# STM32H7R register map
File version: 1.3
CPU: CM7 r0p1, little endian, MPU, FPU, 4 interrupt priority bits
Registers are 32-bit, read-write, reset 0x0 unless marked. A register's access mark holds for its fields unless they carry their own. Offsets are from the block's base; [hi:lo] are bit positions; 'fields as' and 'values as' point back to an identical list.

## SAI1 — Serial audio interface
Base 0x42005800
Same registers: SAI2 0x42005C00
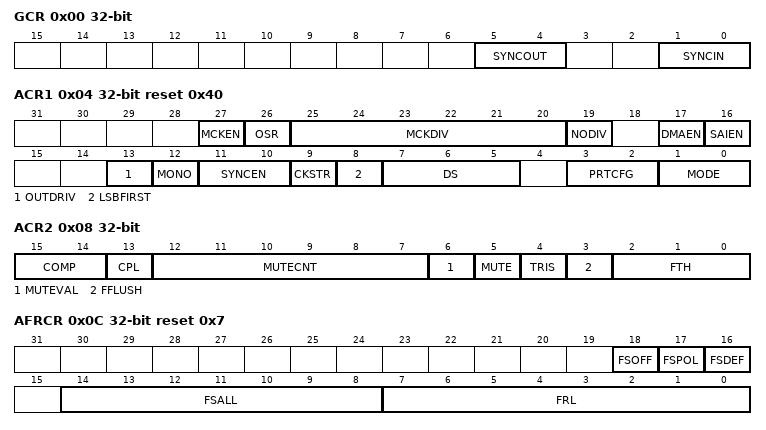
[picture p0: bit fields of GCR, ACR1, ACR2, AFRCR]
0x00 GCR — SAI global configuration register
  [5:4] SYNCOUT — Synchronization outputs These bits are set and cleared by software.
  [1:0] SYNCIN — Synchronization inputs These bits are set and cleared by software. Refer to Table 418: External synchronization selection (TinyShark, Beluga and STM32U5_Cobra2M and 4M, Viper, Mustang, Python) for information on how to program this field. These bits must be set when both audio blocks (A and B) are disabled. They are meaningful if one of the two audio blocks is defined to operate in synchronous mode with an external SAI (SYNCEN[1:0] = 10 in SAI_ACR1 or in SAI_BCR1 registers).
0x04 ACR1 reset 0x40 — SAI configuration register 1
  [27] MCKEN — Master clock generation enable
  [26] OSR — Oversampling ratio for master clock This bit is meaningful only when NODIV bit is set to 0.
  [25:20] MCKDIV — Master clock divider These bits are set and cleared by software. Otherwise, The master clock frequency is calculated according to the formula given in Section 55.4.8: SAI clock generator. These bits have no meaning when the audio block is slave. They have to be configured when the audio block is disabled.
  [19] NODIV — No divider This bit is set and cleared by software.
  [17] DMAEN — DMA enable This bit is set and cleared by software. Note: Since the audio block defaults to operate as a transmitter after reset, the MODE[1:0] bits must be configured before setting DMAEN to avoid a DMA request in receiver mode.
  [16] SAIEN — Audio block enable This bit is set by software. To switch off the audio block, the application software must program this bit to 0 and poll the bit till it reads back 0, meaning that the block is completely disabled. Before setting this bit to 1, check that it is set to 0, otherwise the enable command is not taken into account. This bit enables to control the state of the SAI audio block. If it is disabled when an audio frame transfer is ongoing, the ongoing transfer completes and the cell is fully disabled at the end of this audio frame transfer. Note: When the SAI block (A or B) is configured in master mode, the clock must be present on the SAI block input before setting SAIEN bit.
  [13] OUTDRIV — Output drive This bit is set and cleared by software. Note: This bit has to be set before enabling the audio block and after the audio block configuration.
  [12] MONO — Mono mode This bit is set and cleared by software. It is meaningful only when the number of slots is equal to 2. When the mono mode is selected, slot 0 data are duplicated on slot 1 when the audio block operates as a transmitter. In reception mode, the slot1 is discarded and only the data received from slot 0 are stored. Refer to Section : Mono/stereo mode for more details.
  [11:10] SYNCEN — Synchronization enable These bits are set and cleared by software. They must be configured when the audio subblock is disabled. Note: The audio subblock should be configured as asynchronous when SPDIF mode is enabled.
  [9] CKSTR — Clock strobing edge This bit is set and cleared by software. It must be configured when the audio block is disabled. This bit has no meaning in SPDIF audio protocol.
  [8] LSBFIRST — Least significant bit first This bit is set and cleared by software. It must be configured when the audio block is disabled. This bit has no meaning in AC97 audio protocol since AC97 data are always transferred with the MSB first. This bit has no meaning in SPDIF audio protocol since in SPDIF data are always transferred with LSB first.
  [7:5] DS — Data size These bits are set and cleared by software. These bits are ignored when the SPDIF protocols are selected (bit PRTCFG[1:0]), because the frame and the data size are fixed in such case. When the companding mode is selected through COMP[1:0] bits, DS[1:0] are ignored since the data size is fixed to 8 bits by the algorithm. These bits must be configured when the audio block is disabled.
  [3:2] PRTCFG — Protocol configuration These bits are set and cleared by software. These bits have to be configured when the audio block is disabled.
  [1:0] MODE — SAIx audio block mode These bits are set and cleared by software. They must be configured when SAIx audio block is disabled. Note: When the audio block is configured in SPDIF mode, the master transmitter mode is forced (MODE[1:0] = 00).
0x08 ACR2 access per field — SAI configuration register 2
  [15:14] COMP rw — Companding mode. These bits are set and cleared by software. The -Law and the A-Law log are a part of the CCITT G.711 recommendation, the type of complement that is used depends on CPL bit. The data expansion or data compression are determined by the state of bit MODE[0]. The data compression is applied if the audio block is configured as a transmitter. The data expansion is automatically applied when the audio block is configured as a receiver. Refer to Section : Companding mode for more details. Note: Companding mode is applicable only when Free protocol mode is selected.
  [13] CPL rw — Complement bit. This bit is set and cleared by software. It defines the type of complement to be used for companding mode Note: This bit has effect only when the companding mode is -Law algorithm or A-Law algorithm.
  [12:7] MUTECNT rw — Mute counter. These bits are set and cleared by software. They are used only in reception mode. The value set in these bits is compared to the number of consecutive mute frames detected in reception. When the number of mute frames is equal to this value, the flag MUTEDET is set and an interrupt is generated if bit MUTEDETIE is set. Refer to Section : Mute mode for more details.
  [6] MUTEVAL rw — Mute value. This bit is set and cleared by software.It must be written before enabling the audio block: SAIEN. This bit is meaningful only when the audio block operates as a transmitter, the number of slots is lower or equal to 2 and the MUTE bit is set. If more slots are declared, the bit value sent during the transmission in mute mode is equal to 0, whatever the value of MUTEVAL. if the number of slot is lower or equal to 2 and MUTEVAL = 1, the MUTE value transmitted for each slot is the one sent during the previous frame. Refer to Section : Mute mode for more details. Note: This bit is meaningless and should not be used for SPDIF audio blocks.
  [5] MUTE rw — Mute. This bit is set and cleared by software. It is meaningful only when the audio block operates as a transmitter. The MUTE value is linked to value of MUTEVAL if the number of slots is lower or equal to 2, or equal to 0 if it is greater than 2. Refer to Section : Mute mode for more details. Note: This bit is meaningless and should not be used for SPDIF audio blocks.
  [4] TRIS rw — Tristate management on data line. This bit is set and cleared by software. It is meaningful only if the audio block is configured as a transmitter. This bit is not used when the audio block is configured in SPDIF mode. It should be configured when SAI is disabled. Refer to Section : Output data line management on an inactive slot for more details.
  [3] FFLUSH wo — FIFO flush. This bit is set by software. It is always read as 0. This bit should be configured when the SAI is disabled.
  [2:0] FTH rw — FIFO threshold. This bit is set and cleared by software.
0x0C AFRCR reset 0x7 — SAI frame configuration register
  [18] FSOFF — Frame synchronization offset. This bit is set and cleared by software. It is meaningless and is not used in AC97 or SPDIF audio block configuration. This bit must be configured when the audio block is disabled.
  [17] FSPOL — Frame synchronization polarity. This bit is set and cleared by software. It is used to configure the level of the start of frame on the FS signal. It is meaningless and is not used in AC97 or SPDIF audio block configuration. This bit must be configured when the audio block is disabled.
  [16] FSDEF — Frame synchronization definition. This bit is set and cleared by software. When the bit is set, the number of slots defined in the SAI_xSLOTR register has to be even. It means that half of this number of slots are dedicated to the left channel and the other slots for the right channel (e.g: this bit has to be set for I2S or MSB/LSB-justified protocols...). This bit is meaningless and is not used in AC97 or SPDIF audio block configuration. It must be configured when the audio block is disabled.
  [14:8] FSALL — Frame synchronization active level length. These bits are set and cleared by software. They specify the length in number of bit clock (SCK) + 1 (FSALL[6:0] + 1) of the active level of the FS signal in the audio frame These bits are meaningless and are not used in AC97 or SPDIF audio block configuration. They must be configured when the audio block is disabled.
  [7:0] FRL — Frame length. These bits are set and cleared by software. They define the audio frame length expressed in number of SCK clock cycles: the number of bits in the frame is equal to FRL[7:0] + 1. The minimum number of bits to transfer in an audio frame must be equal to 8, otherwise the audio block behaves in an unexpected way. This is the case when the data size is 8 bits and only one slot 0 is defined in NBSLOT[4:0] of SAI_xSLOTR register (NBSLOT[3:0] = 0000). In master mode, if the master clock (available on MCLK_x pin) is used, the frame length should be aligned with a number equal to a power of 2, ranging from 8 to 256. When the master clock is not used (NODIV = 1), it is recommended to program the frame length to an value ranging from 8 to 256. These bits are meaningless and are not used in AC97 or SPDIF audio block configuration. They must be configured when the audio block is disabled.
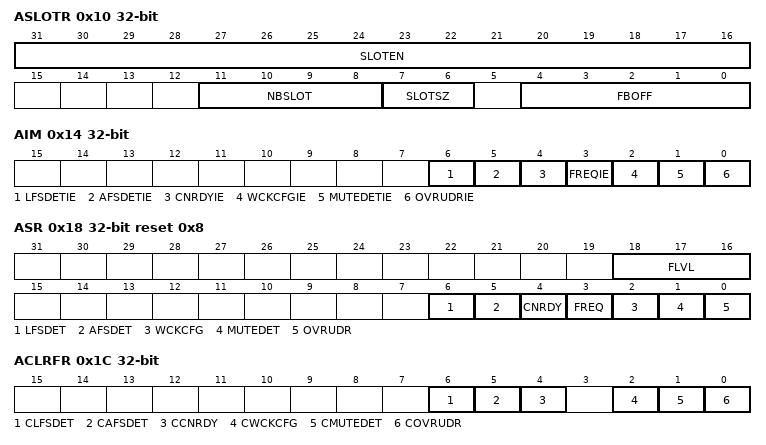
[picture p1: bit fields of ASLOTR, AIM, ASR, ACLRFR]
0x10 ASLOTR — SAI slot register
  [31:16] SLOTEN — Slot enable. These bits are set and cleared by software. Each SLOTEN bit corresponds to a slot position from 0 to 15 (maximum 16 slots). The slot must be enabled when the audio block is disabled. They are ignored in AC97 or SPDIF mode.
  [11:8] NBSLOT — Number of slots in an audio frame. These bits are set and cleared by software. The value set in this bitfield represents the number of slots + 1 in the audio frame (including the number of inactive slots). The maximum number of slots is 16. The number of slots should be even if FSDEF bit in the SAI_xFRCR register is set. The number of slots must be configured when the audio block is disabled. They are ignored in AC97 or SPDIF mode.
  [7:6] SLOTSZ — Slot size This bits is set and cleared by software. The slot size must be higher or equal to the data size. If this condition is not respected, the behavior of the SAI is undetermined. Refer to Output data line management on an inactive slot for information on how to drive SD line. These bits must be set when the audio block is disabled. They are ignored in AC97 or SPDIF mode.
  [4:0] FBOFF — First bit offset These bits are set and cleared by software. The value set in this bitfield defines the position of the first data transfer bit in the slot. It represents an offset value. In transmission mode, the bits outside the data field are forced to 0. In reception mode, the extra received bits are discarded. These bits must be set when the audio block is disabled. They are ignored in AC97 or SPDIF mode.
0x14 AIM — SAI interrupt mask register
  [6] LFSDETIE — Late frame synchronization detection interrupt enable. This bit is set and cleared by software. When this bit is set, an interrupt is generated if the LFSDET bit is set in the SAI_xSR register. This bit is meaningless in AC97, SPDIF mode or when the audio block operates as a master.
  [5] AFSDETIE — Anticipated frame synchronization detection interrupt enable. This bit is set and cleared by software. When this bit is set, an interrupt is generated if the AFSDET bit in the SAI_xSR register is set. This bit is meaningless in AC97, SPDIF mode or when the audio block operates as a master.
  [4] CNRDYIE — Codec not ready interrupt enable (AC97). This bit is set and cleared by software. When the interrupt is enabled, the audio block detects in the slot 0 (tag0) of the AC97 frame if the Codec connected to this line is ready or not. If it is not ready, the CNRDY flag in the SAI_xSR register is set and an interrupt is generated. This bit has a meaning only if the AC97 mode is selected through PRTCFG[1:0] bits and the audio block is operates as a receiver.
  [3] FREQIE — FIFO request interrupt enable. This bit is set and cleared by software. When this bit is set, an interrupt is generated if the FREQ bit in the SAI_xSR register is set. Since the audio block defaults to operate as a transmitter after reset, the MODE bit must be configured before setting FREQIE to avoid a parasitic interrupt in receiver mode,
  [2] WCKCFGIE — Wrong clock configuration interrupt enable. This bit is set and cleared by software. This bit is taken into account only if the audio block is configured as a master (MODE[1] = 0) and NODIV = 0. It generates an interrupt if the WCKCFG flag in the SAI_xSR register is set. Note: This bit is used only in Free protocol mode and is meaningless in other modes.
  [1] MUTEDETIE — Mute detection interrupt enable. This bit is set and cleared by software. When this bit is set, an interrupt is generated if the MUTEDET bit in the SAI_xSR register is set. This bit has a meaning only if the audio block is configured in receiver mode.
  [0] OVRUDRIE — Overrun/underrun interrupt enable. This bit is set and cleared by software. When this bit is set, an interrupt is generated if the OVRUDR bit in the SAI_xSR register is set.
0x18 ASR ro reset 0x8 — SAI status register
  [18:16] FLVL — FIFO level threshold. This bit is read only. The FIFO level threshold flag is managed only by hardware and its setting depends on SAI block configuration (transmitter or receiver mode). Others: Reserved
  [6] LFSDET — Late frame synchronization detection. This bit is read only. This flag can be set only if the audio block is configured in slave mode. It is not used in AC97 or SPDIF mode. It can generate an interrupt if LFSDETIE bit is set in the SAI_xIM register. This flag is cleared when the software sets bit CLFSDET in SAI_xCLRFR register
  [5] AFSDET — Anticipated frame synchronization detection. This bit is read only. This flag can be set only if the audio block is configured in slave mode. It is not used in AC97 or SPDIF mode. It can generate an interrupt if AFSDETIE bit is set in SAI_xIM register. This flag is cleared when the software sets CAFSDET bit in SAI_xCLRFR register.
  [4] CNRDY — Codec not ready. This bit is read only. This bit is used only when the AC97 audio protocol is selected in the SAI_xCR1 register and configured in receiver mode. It can generate an interrupt if CNRDYIE bit is set in SAI_xIM register. This flag is cleared when the software sets CCNRDY bit in SAI_xCLRFR register.
  [3] FREQ — FIFO request. This bit is read only. The request depends on the audio block configuration: If the block is configured in transmission mode, the FIFO request is related to a write request operation in the SAI_xDR. If the block configured in reception, the FIFO request related to a read request operation from the SAI_xDR. This flag can generate an interrupt if FREQIE bit is set in SAI_xIM register.
  [2] WCKCFG — Wrong clock configuration flag. This bit is read only. This bit is used only when the audio block operates in master mode (MODE[1] = 0) and NODIV = 0. It can generate an interrupt if WCKCFGIE bit is set in SAI_xIM register. This flag is cleared when the software sets CWCKCFG bit in SAI_xCLRFR register.
  [1] MUTEDET — Mute detection. This bit is read only. This flag is set if consecutive 0 values are received in each slot of a given audio frame and for a consecutive number of audio frames (set in the MUTECNT bit in the SAI_xCR2 register). It can generate an interrupt if MUTEDETIE bit is set in SAI_xIM register. This flag is cleared when the software sets bit CMUTEDET in the SAI_xCLRFR register.
  [0] OVRUDR — Overrun / underrun. This bit is read only. The overrun and underrun conditions can occur only when the audio block is configured as a receiver and a transmitter, respectively. It can generate an interrupt if OVRUDRIE bit is set in SAI_xIM register. This flag is cleared when the software sets COVRUDR bit in SAI_xCLRFR register.
0x1C ACLRFR wo — SAI clear flag register
  [6] CLFSDET — Clear late frame synchronization detection flag. This bit is write only. Programming this bit to 1 clears the LFSDET flag in the SAI_xSR register. This bit is not used in AC97 or SPDIF mode Reading this bit always returns the value 0.
  [5] CAFSDET — Clear anticipated frame synchronization detection flag. This bit is write only. Programming this bit to 1 clears the AFSDET flag in the SAI_xSR register. It is not used in AC97 or SPDIF mode. Reading this bit always returns the value 0.
  [4] CCNRDY — Clear Codec not ready flag. This bit is write only. Programming this bit to 1 clears the CNRDY flag in the SAI_xSR register. This bit is used only when the AC97 audio protocol is selected in the SAI_xCR1 register. Reading this bit always returns the value 0.
  [2] CWCKCFG — Clear wrong clock configuration flag. This bit is write only. Programming this bit to 1 clears the WCKCFG flag in the SAI_xSR register. This bit is used only when the audio block is set as master (MODE[1] = 0) and NODIV = 0 in the SAI_xCR1 register. Reading this bit always returns the value 0.
  [1] CMUTEDET — Mute detection flag. This bit is write only. Programming this bit to 1 clears the MUTEDET flag in the SAI_xSR register. Reading this bit always returns the value 0.
  [0] COVRUDR — Clear overrun / underrun. This bit is write only. Programming this bit to 1 clears the OVRUDR flag in the SAI_xSR register. Reading this bit always returns the value 0.
0x20 ADR — SAI data register
  [31:0] DATA — Data A write to this register loads the FIFO provided the FIFO is not full. A read from this register empties the FIFO if the FIFO is not empty.
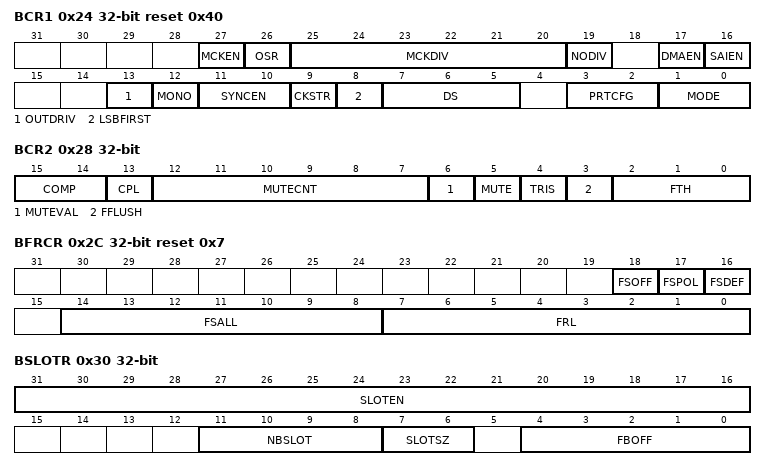
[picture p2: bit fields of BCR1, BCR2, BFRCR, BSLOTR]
0x24 BCR1 reset 0x40 — SAI configuration register 1
  [27] MCKEN — Master clock generation enable
  [26] OSR — Oversampling ratio for master clock This bit is meaningful only when NODIV bit is set to 0.
  [25:20] MCKDIV — Master clock divider These bits are set and cleared by software. Otherwise, The master clock frequency is calculated according to the formula given in Section 55.4.8: SAI clock generator. These bits have no meaning when the audio block is slave. They have to be configured when the audio block is disabled.
  [19] NODIV — No divider This bit is set and cleared by software.
  [17] DMAEN — DMA enable This bit is set and cleared by software. Note: Since the audio block defaults to operate as a transmitter after reset, the MODE[1:0] bits must be configured before setting DMAEN to avoid a DMA request in receiver mode.
  [16] SAIEN — Audio block enable This bit is set by software. To switch off the audio block, the application software must program this bit to 0 and poll the bit till it reads back 0, meaning that the block is completely disabled. Before setting this bit to 1, check that it is set to 0, otherwise the enable command is not taken into account. This bit enables to control the state of the SAI audio block. If it is disabled when an audio frame transfer is ongoing, the ongoing transfer completes and the cell is fully disabled at the end of this audio frame transfer. Note: When the SAI block (A or B) is configured in master mode, the clock must be present on the SAI block input before setting SAIEN bit.
  [13] OUTDRIV — Output drive This bit is set and cleared by software. Note: This bit has to be set before enabling the audio block and after the audio block configuration.
  [12] MONO — Mono mode This bit is set and cleared by software. It is meaningful only when the number of slots is equal to 2. When the mono mode is selected, slot 0 data are duplicated on slot 1 when the audio block operates as a transmitter. In reception mode, the slot1 is discarded and only the data received from slot 0 are stored. Refer to Section : Mono/stereo mode for more details.
  [11:10] SYNCEN — Synchronization enable These bits are set and cleared by software. They must be configured when the audio subblock is disabled. Note: The audio subblock should be configured as asynchronous when SPDIF mode is enabled.
  [9] CKSTR — Clock strobing edge This bit is set and cleared by software. It must be configured when the audio block is disabled. This bit has no meaning in SPDIF audio protocol.
  [8] LSBFIRST — Least significant bit first This bit is set and cleared by software. It must be configured when the audio block is disabled. This bit has no meaning in AC97 audio protocol since AC97 data are always transferred with the MSB first. This bit has no meaning in SPDIF audio protocol since in SPDIF data are always transferred with LSB first.
  [7:5] DS — Data size These bits are set and cleared by software. These bits are ignored when the SPDIF protocols are selected (bit PRTCFG[1:0]), because the frame and the data size are fixed in such case. When the companding mode is selected through COMP[1:0] bits, DS[1:0] are ignored since the data size is fixed to 8 bits by the algorithm. These bits must be configured when the audio block is disabled.
  [3:2] PRTCFG — Protocol configuration These bits are set and cleared by software. These bits have to be configured when the audio block is disabled.
  [1:0] MODE — SAIx audio block mode These bits are set and cleared by software. They must be configured when SAIx audio block is disabled. Note: When the audio block is configured in SPDIF mode, the master transmitter mode is forced (MODE[1:0] = 00). In Master transmitter mode, the audio block starts generating the FS and the clocks immediately.
0x28 BCR2 access per field — SAI configuration register 2
  fields as ACR2
0x2C BFRCR reset 0x7 — SAI frame configuration register
  [18] FSOFF — Frame synchronization offset. This bit is set and cleared by software. It is meaningless and is not used in AC97 or SPDIF audio block configuration. This bit must be configured when the audio block is disabled.
  [17] FSPOL — Frame synchronization polarity. This bit is set and cleared by software. It is used to configure the level of the start of frame on the FS signal. It is meaningless and is not used in AC97 or SPDIF audio block configuration. This bit must be configured when the audio block is disabled.
  [16] FSDEF — Frame synchronization definition. This bit is set and cleared by software. When the bit is set, the number of slots defined in the SAI_xSLOTR register has to be even. It means that half of this number of slots is dedicated to the left channel and the other slots for the right channel (e.g: this bit has to be set for I2S or MSB/LSB-justified protocols...). This bit is meaningless and is not used in AC97 or SPDIF audio block configuration. It must be configured when the audio block is disabled.
  [14:8] FSALL — Frame synchronization active level length. These bits are set and cleared by software. They specify the length in number of bit clock (SCK) + 1 (FSALL[6:0] + 1) of the active level of the FS signal in the audio frame These bits are meaningless and are not used in AC97 or SPDIF audio block configuration. They must be configured when the audio block is disabled.
  [7:0] FRL — Frame length. These bits are set and cleared by software. They define the audio frame length expressed in number of SCK clock cycles: the number of bits in the frame is equal to FRL[7:0] + 1. The minimum number of bits to transfer in an audio frame must be equal to 8, otherwise the audio block behaves in an unexpected way. This is the case when the data size is 8 bits and only one slot 0 is defined in NBSLOT[4:0] of SAI_xSLOTR register (NBSLOT[3:0] = 0000). In master mode, if the master clock (available on MCLK_x pin) is used, the frame length should be aligned with a number equal to a power of 2, ranging from 8 to 256. When the master clock is not used (NODIV = 1), it is recommended to program the frame length to an value ranging from 8 to 256. These bits are meaningless and are not used in AC97 or SPDIF audio block configuration.
0x30 BSLOTR — SAI slot register
  fields as ASLOTR
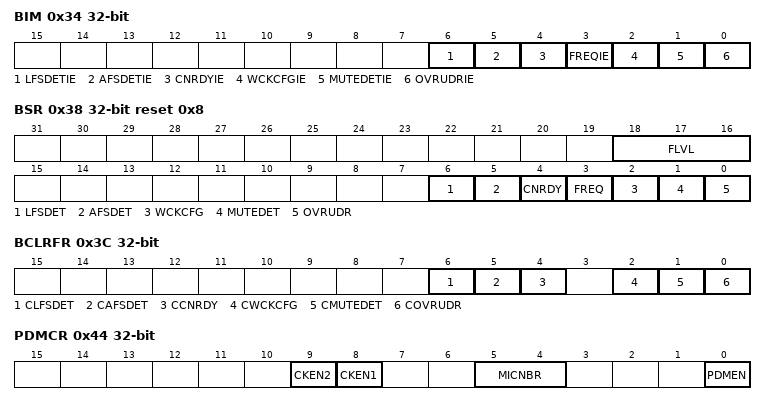
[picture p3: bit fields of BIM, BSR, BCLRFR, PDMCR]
0x34 BIM — SAI interrupt mask register
  fields as AIM
0x38 BSR ro reset 0x8 — SAI status register
  [18:16] FLVL — FIFO level threshold. This bit is read only. The FIFO level threshold flag is managed only by hardware and its setting depends on SAI block configuration (transmitter or receiver mode). Others: Reserved
  [6] LFSDET — Late frame synchronization detection. This bit is read only. This flag can be set only if the audio block is configured in slave mode. It is not used in AC97 or SPDIF mode. It can generate an interrupt if LFSDETIE bit is set in the SAI_xIM register. This flag is cleared when the software sets bit CLFSDET in SAI_xCLRFR register
  [5] AFSDET — Anticipated frame synchronization detection. This bit is read only. This flag can be set only if the audio block is configured in slave mode. It is not used in AC97or SPDIF mode. It can generate an interrupt if AFSDETIE bit is set in SAI_xIM register. This flag is cleared when the software sets CAFSDET bit in SAI_xCLRFR register.
  [4] CNRDY — Codec not ready. This bit is read only. This bit is used only when the AC97 audio protocol is selected in the SAI_xCR1 register and configured in receiver mode. It can generate an interrupt if CNRDYIE bit is set in SAI_xIM register. This flag is cleared when the software sets CCNRDY bit in SAI_xCLRFR register.
  [3] FREQ — FIFO request. This bit is read only. The request depends on the audio block configuration: If the block is configured in transmission mode, the FIFO request is related to a write request operation in the SAI_xDR. If the block configured in reception, the FIFO request related to a read request operation from the SAI_xDR. This flag can generate an interrupt if FREQIE bit is set in SAI_xIM register.
  [2] WCKCFG — Wrong clock configuration flag. This bit is read only. This bit is used only when the audio block operates in master mode (MODE[1] = 0) and NODIV = 0. It can generate an interrupt if WCKCFGIE bit is set in SAI_xIM register. This flag is cleared when the software sets CWCKCFG bit in SAI_xCLRFR register.
  [1] MUTEDET — Mute detection. This bit is read only. This flag is set if consecutive 0 values are received in each slot of a given audio frame and for a consecutive number of audio frames (set in the MUTECNT bit in the SAI_xCR2 register). It can generate an interrupt if MUTEDETIE bit is set in SAI_xIM register. This flag is cleared when the software sets bit CMUTEDET in the SAI_xCLRFR register.
  [0] OVRUDR — Overrun / underrun. This bit is read only. The overrun and underrun conditions can occur only when the audio block is configured as a receiver and a transmitter, respectively. It can generate an interrupt if OVRUDRIE bit is set in SAI_xIM register. This flag is cleared when the software sets COVRUDR bit in SAI_xCLRFR register.
0x3C BCLRFR wo — SAI clear flag register
  [6] CLFSDET — Clear late frame synchronization detection flag. This bit is write only. Programming this bit to 1 clears the LFSDET flag in the SAI_xSR register. This bit is not used in AC97or SPDIF mode Reading this bit always returns the value 0.
  [5] CAFSDET — Clear anticipated frame synchronization detection flag. This bit is write only. Programming this bit to 1 clears the AFSDET flag in the SAI_xSR register. It is not used in AC97or SPDIF mode. Reading this bit always returns the value 0.
  [4] CCNRDY — Clear Codec not ready flag. This bit is write only. Programming this bit to 1 clears the CNRDY flag in the SAI_xSR register. This bit is used only when the AC97 audio protocol is selected in the SAI_xCR1 register. Reading this bit always returns the value 0.
  [2] CWCKCFG — Clear wrong clock configuration flag. This bit is write only. Programming this bit to 1 clears the WCKCFG flag in the SAI_xSR register. This bit is used only when the audio block is set as master (MODE[1] = 0) and NODIV = 0 in the SAI_xCR1 register. Reading this bit always returns the value 0.
  [1] CMUTEDET — Mute detection flag. This bit is write only. Programming this bit to 1 clears the MUTEDET flag in the SAI_xSR register. Reading this bit always returns the value 0.
  [0] COVRUDR — Clear overrun / underrun. This bit is write only. Programming this bit to 1 clears the OVRUDR flag in the SAI_xSR register. Reading this bit always returns the value 0.
0x40 BDR — SAI data register
  fields as ADR
0x44 PDMCR — SAI PDM control register
  [9] CKEN2 — Clock enable of bitstream clock number 2 This bit is set and cleared by software. Note: It is not recommended to configure this bit when PDMEN = 1. Note: SAI_CK2 might not be available for all SAI instances. Refer to Section 55.3: SAI implementation for details.
  [8] CKEN1 — Clock enable of bitstream clock number 1 This bit is set and cleared by software. Note: It is not recommended to configure this bit when PDMEN = 1. Note: SAI_CK1 might not be available for all SAI instances. Refer to Section 55.3: SAI implementation for details.
  [5:4] MICNBR — Number of microphones This bit is set and cleared by software. Note: It is not recommended to configure this field when PDMEN = 1.* Note: The complete set of data lines might not be available for all SAI instances. Refer to Section 55.3: SAI implementation for details.
  [0] PDMEN — PDM enable This bit is set and cleared by software. This bit enables to control the state of the PDM interface block. Make sure that the SAI in already operating in TDM master mode before enabling the PDM interface.
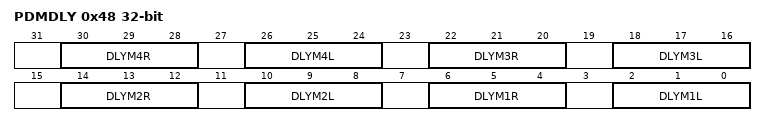
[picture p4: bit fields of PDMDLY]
0x48 PDMDLY — SAI PDM delay register
  [30:28] DLYM4R — Delay line for second microphone of pair 4 This bit is set and cleared by software. ... This field can be changed on-the-fly. Note: This field can be used only if D4 line is available.Refer to Section 55.3: SAI implementation to check if it is available.
  [26:24] DLYM4L — Delay line for first microphone of pair 4 This bit is set and cleared by software. ... This field can be changed on-the-fly. Note: This field can be used only if D4 line is available.Refer to Section 55.3: SAI implementation to check if it is available.
  [22:20] DLYM3R — Delay line for second microphone of pair 3 This bit is set and cleared by software. ... This field can be changed on-the-fly. Note: This field can be used only if D3 line is available.Refer to Section 55.3: SAI implementation to check if it is available.
  [18:16] DLYM3L — Delay line for first microphone of pair 3 This bit is set and cleared by software. ... This field can be changed on-the-fly. Note: This field can be used only if D3 line is available.Refer to Section 55.3: SAI implementation to check if it is available.
  [14:12] DLYM2R — Delay line for second microphone of pair 2 This bit is set and cleared by software. ... This field can be changed on-the-fly. Note: This field can be used only if D2 line is available.Refer to Section 55.3: SAI implementation to check if it is available.
  [10:8] DLYM2L — Delay line for first microphone of pair 2 This bit is set and cleared by software. ... This field can be changed on-the-fly. Note: This field can be used only if D2 line is available.Refer to Section 55.3: SAI implementation to check if it is available.
  [6:4] DLYM1R — Delay line adjust for second microphone of pair 1 This bit is set and cleared by software. ... This field can be changed on-the-fly. Note: This field can be used only if D1 line is available.Refer to Section 55.3: SAI implementation to check if it is available.
  [2:0] DLYM1L — Delay line adjust for first microphone of pair 1 This bit is set and cleared by software. ... This field can be changed on-the-fly. Note: This field can be used only if D1 line is available.Refer to Section 55.3: SAI implementation to check if it is available.
